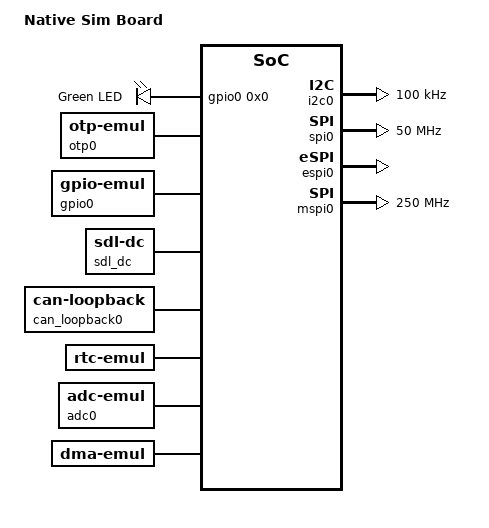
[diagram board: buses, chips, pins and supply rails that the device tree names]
/dts-v1/;

/* node '/' defined in zephyr/dts/common/skeleton.dtsi:9 */
/ {
	#address-cells = < 0x1 >;    /* in zephyr/dts/common/skeleton.dtsi:10 */
	#size-cells = < 0x1 >;       /* in zephyr/dts/common/skeleton.dtsi:11 */
	model = "Native Sim Board";  /* in zephyr/boards/native/native_sim/native_sim.dts:16 */
	compatible = "zephyr,posix"; /* in zephyr/boards/native/native_sim/native_sim.dts:17 */

	/* node '/chosen' defined in zephyr/dts/common/skeleton.dtsi:13 */
	chosen {
		zephyr,console = &uart0;                     /* in zephyr/boards/native/native_sim/native_sim.dts:20 */
		zephyr,shell-uart = &uart0;                  /* in zephyr/boards/native/native_sim/native_sim.dts:21 */
		zephyr,uart-mcumgr = &uart0;                 /* in zephyr/boards/native/native_sim/native_sim.dts:22 */
		zephyr,flash = &flash0;                      /* in zephyr/boards/native/native_sim/native_sim.dts:23 */
		zephyr,entropy = &rng;                       /* in zephyr/boards/native/native_sim/native_sim.dts:24 */
		zephyr,flash-controller = &flashcontroller0; /* in zephyr/boards/native/native_sim/native_sim.dts:25 */
		zephyr,display = &sdl_dc;                    /* in zephyr/boards/native/native_sim/native_sim.dts:26 */
		zephyr,canbus = &can_loopback0;              /* in zephyr/boards/native/native_sim/native_sim.dts:27 */
		zephyr,code-partition = &slot0_partition;    /* in zephyr/boards/native/native_sim/native_sim.dts:28 */
		zephyr,bt-hci = &bt_hci_userchan;            /* in zephyr/boards/native/native_sim/native_sim.dts:29 */
		zephyr,touch = &input_sdl_touch;             /* in zephyr/boards/native/native_sim/native_sim.dts:30 */
	};

	/* node '/aliases' defined in zephyr/dts/common/skeleton.dtsi:15 */
	aliases {
		codec0 = &audio_codec; /* in zephyr/boards/native/native_sim/native_sim.dts:34 */
		dmic0 = &dmic0;        /* in zephyr/boards/native/native_sim/native_sim.dts:35 */
		eeprom-0 = &eeprom0;   /* in zephyr/boards/native/native_sim/native_sim.dts:36 */
		i2c-0 = &i2c0;         /* in zephyr/boards/native/native_sim/native_sim.dts:37 */
		i2s-node0 = &i2s_rxtx; /* in zephyr/boards/native/native_sim/native_sim.dts:38 */
		spi-0 = &spi0;         /* in zephyr/boards/native/native_sim/native_sim.dts:39 */
		led0 = &led0;          /* in zephyr/boards/native/native_sim/native_sim.dts:40 */
		rtc = &rtc;            /* in zephyr/boards/native/native_sim/native_sim.dts:41 */
	};

	/* node '/leds' defined in zephyr/boards/native/native_sim/native_sim.dts:44 */
	leds: leds {
		compatible = "gpio-leds"; /* in zephyr/boards/native/native_sim/native_sim.dts:45 */

		/* node '/leds/led_0' defined in zephyr/boards/native/native_sim/native_sim.dts:47 */
		led0: led_0 {
			gpios = < &gpio0 0x0 0x0 >; /* in zephyr/boards/native/native_sim/native_sim.dts:48 */
			label = "Green LED";        /* in zephyr/boards/native/native_sim/native_sim.dts:49 */
		};
	};

	/* node '/cpus' defined in zephyr/boards/native/native_sim/native_sim.dts:53 */
	cpus {
		timebase-frequency = < 0xf4240 >; /* in zephyr/boards/native/native_sim/native_sim.dts:54 */
		#address-cells = < 0x1 >;         /* in zephyr/boards/native/native_sim/native_sim.dts:55 */
		#size-cells = < 0x0 >;            /* in zephyr/boards/native/native_sim/native_sim.dts:56 */

		/* node '/cpus/cpu@0' defined in zephyr/boards/native/native_sim/native_sim.dts:58 */
		cpu0: cpu@0 {
			compatible = "zephyr,native-sim-cpu"; /* in zephyr/boards/native/native_sim/native_sim.dts:59 */
			reg = < 0x0 >;                        /* in zephyr/boards/native/native_sim/native_sim.dts:60 */
		};
	};

	/* node '/flash-controller@0' defined in zephyr/boards/native/native_sim/native_sim.dts:64 */
	flashcontroller0: flash-controller@0 {
		compatible = "zephyr,sim-flash"; /* in zephyr/boards/native/native_sim/native_sim.dts:65 */
		reg = < 0x0 0x200000 >;          /* in zephyr/boards/native/native_sim/native_sim.dts:66 */
		ranges;                          /* in zephyr/boards/native/native_sim/native_sim.dts:67 */
		#address-cells = < 0x1 >;        /* in zephyr/boards/native/native_sim/native_sim.dts:69 */
		#size-cells = < 0x1 >;           /* in zephyr/boards/native/native_sim/native_sim.dts:70 */
		erase-value = < 0xff >;          /* in zephyr/boards/native/native_sim/native_sim.dts:71 */

		/* node '/flash-controller@0/flash@0' defined in zephyr/boards/native/native_sim/native_sim.dts:73 */
		flash0: flash@0 {
			status = "okay";               /* in zephyr/boards/native/native_sim/native_sim.dts:74 */
			compatible = "soc-nv-flash";   /* in zephyr/boards/native/native_sim/native_sim.dts:75 */
			erase-block-size = < 0x1000 >; /* in zephyr/boards/native/native_sim/native_sim.dts:76 */
			write-block-size = < 0x1 >;    /* in zephyr/boards/native/native_sim/native_sim.dts:77 */
			reg = < 0x0 0x200000 >;        /* in zephyr/boards/native/native_sim/native_sim.dts:78 */
			ranges = < 0x0 0x0 0x200000 >; /* in zephyr/boards/native/native_sim/native_sim.dts:79 */
			#address-cells = < 0x1 >;      /* in zephyr/boards/native/native_sim/native_sim.dts:80 */
			#size-cells = < 0x1 >;         /* in zephyr/boards/native/native_sim/native_sim.dts:81 */

			/* node '/flash-controller@0/flash@0/partitions' defined in zephyr/boards/native/native_sim/native_sim.dts:83 */
			partitions {
				ranges;                   /* in zephyr/boards/native/native_sim/native_sim.dts:84 */
				#address-cells = < 0x1 >; /* in zephyr/boards/native/native_sim/native_sim.dts:85 */
				#size-cells = < 0x1 >;    /* in zephyr/boards/native/native_sim/native_sim.dts:86 */

				/* node '/flash-controller@0/flash@0/partitions/partition@0' defined in zephyr/boards/native/native_sim/native_sim.dts:88 */
				boot_partition: partition@0 {
					compatible = "zephyr,mapped-partition"; /* in zephyr/boards/native/native_sim/native_sim.dts:89 */
					label = "mcuboot";                      /* in zephyr/boards/native/native_sim/native_sim.dts:90 */
					reg = < 0x0 0xc000 >;                   /* in zephyr/boards/native/native_sim/native_sim.dts:91 */
				};

				/* node '/flash-controller@0/flash@0/partitions/partition@c000' defined in zephyr/boards/native/native_sim/native_sim.dts:94 */
				slot0_partition: partition@c000 {
					compatible = "zephyr,mapped-partition"; /* in zephyr/boards/native/native_sim/native_sim.dts:95 */
					label = "image-0";                      /* in zephyr/boards/native/native_sim/native_sim.dts:96 */
					reg = < 0xc000 0x69000 >;               /* in zephyr/boards/native/native_sim/native_sim.dts:97 */
				};

				/* node '/flash-controller@0/flash@0/partitions/partition@75000' defined in zephyr/boards/native/native_sim/native_sim.dts:100 */
				slot1_partition: partition@75000 {
					compatible = "zephyr,mapped-partition"; /* in zephyr/boards/native/native_sim/native_sim.dts:101 */
					label = "image-1";                      /* in zephyr/boards/native/native_sim/native_sim.dts:102 */
					reg = < 0x75000 0x69000 >;              /* in zephyr/boards/native/native_sim/native_sim.dts:103 */
				};

				/* node '/flash-controller@0/flash@0/partitions/partition@de000' defined in zephyr/boards/native/native_sim/native_sim.dts:106 */
				scratch_partition: partition@de000 {
					compatible = "zephyr,mapped-partition"; /* in zephyr/boards/native/native_sim/native_sim.dts:107 */
					label = "image-scratch";                /* in zephyr/boards/native/native_sim/native_sim.dts:108 */
					reg = < 0xde000 0x1e000 >;              /* in zephyr/boards/native/native_sim/native_sim.dts:109 */
				};

				/* node '/flash-controller@0/flash@0/partitions/partition@fc000' defined in zephyr/boards/native/native_sim/native_sim.dts:112 */
				storage_partition: partition@fc000 {
					compatible = "zephyr,mapped-partition"; /* in zephyr/boards/native/native_sim/native_sim.dts:113 */
					label = "storage";                      /* in zephyr/boards/native/native_sim/native_sim.dts:114 */
					reg = < 0xfc000 0x4000 >;               /* in zephyr/boards/native/native_sim/native_sim.dts:115 */
				};
			};
		};
	};

	/* node '/eeprom' defined in zephyr/boards/native/native_sim/native_sim.dts:121 */
	eeprom0: eeprom {
		status = "okay";                  /* in zephyr/boards/native/native_sim/native_sim.dts:122 */
		compatible = "zephyr,sim-eeprom"; /* in zephyr/boards/native/native_sim/native_sim.dts:123 */
		size = < 0x8000 >;                /* in zephyr/boards/native/native_sim/native_sim.dts:124 */
	};

	/* node '/otp' defined in zephyr/boards/native/native_sim/native_sim.dts:127 */
	otp0: otp {
		compatible = "zephyr,otp-emul"; /* in zephyr/boards/native/native_sim/native_sim.dts:128 */
		size = < 0x400 >;               /* in zephyr/boards/native/native_sim/native_sim.dts:129 */
		status = "okay";                /* in zephyr/boards/native/native_sim/native_sim.dts:130 */
	};

	/* node '/i2c@100' defined in zephyr/boards/native/native_sim/native_sim.dts:133 */
	i2c0: i2c@100 {
		status = "okay";                           /* in zephyr/boards/native/native_sim/native_sim.dts:134 */
		compatible = "zephyr,i2c-emul-controller"; /* in zephyr/boards/native/native_sim/native_sim.dts:135 */
		clock-frequency = < 0x186a0 >;             /* in zephyr/boards/native/native_sim/native_sim.dts:136 */
		#address-cells = < 0x1 >;                  /* in zephyr/boards/native/native_sim/native_sim.dts:137 */
		#size-cells = < 0x0 >;                     /* in zephyr/boards/native/native_sim/native_sim.dts:138 */
		#forward-cells = < 0x1 >;                  /* in zephyr/boards/native/native_sim/native_sim.dts:139 */
		reg = < 0x100 0x4 >;                       /* in zephyr/boards/native/native_sim/native_sim.dts:140 */
	};

	/* node '/spi@200' defined in zephyr/boards/native/native_sim/native_sim.dts:143 */
	spi0: spi@200 {
		status = "okay";                           /* in zephyr/boards/native/native_sim/native_sim.dts:144 */
		compatible = "zephyr,spi-emul-controller"; /* in zephyr/boards/native/native_sim/native_sim.dts:145 */
		clock-frequency = < 0x2faf080 >;           /* in zephyr/boards/native/native_sim/native_sim.dts:146 */
		#address-cells = < 0x1 >;                  /* in zephyr/boards/native/native_sim/native_sim.dts:147 */
		#size-cells = < 0x0 >;                     /* in zephyr/boards/native/native_sim/native_sim.dts:148 */
		reg = < 0x200 0x4 >;                       /* in zephyr/boards/native/native_sim/native_sim.dts:149 */
	};

	/* node '/espi@300' defined in zephyr/boards/native/native_sim/native_sim.dts:152 */
	espi0: espi@300 {
		status = "okay";                            /* in zephyr/boards/native/native_sim/native_sim.dts:153 */
		compatible = "zephyr,espi-emul-controller"; /* in zephyr/boards/native/native_sim/native_sim.dts:154 */
		reg = < 0x300 0x4 >;                        /* in zephyr/boards/native/native_sim/native_sim.dts:155 */
		#address-cells = < 0x1 >;                   /* in zephyr/boards/native/native_sim/native_sim.dts:156 */
		#size-cells = < 0x0 >;                      /* in zephyr/boards/native/native_sim/native_sim.dts:157 */
	};

	/* node '/mspi@400' defined in zephyr/boards/native/native_sim/native_sim.dts:160 */
	mspi0: mspi@400 {
		status = "okay";                            /* in zephyr/boards/native/native_sim/native_sim.dts:161 */
		compatible = "zephyr,mspi-emul-controller"; /* in zephyr/boards/native/native_sim/native_sim.dts:162 */
		clock-frequency = < 0xee6b280 >;            /* in zephyr/boards/native/native_sim/native_sim.dts:163 */
		reg = < 0x400 0x4 >;                        /* in zephyr/boards/native/native_sim/native_sim.dts:164 */
		#address-cells = < 0x1 >;                   /* in zephyr/boards/native/native_sim/native_sim.dts:165 */
		#size-cells = < 0x0 >;                      /* in zephyr/boards/native/native_sim/native_sim.dts:166 */
	};

	/* node '/uart' defined in zephyr/boards/native/native_sim/native_sim.dts:169 */
	uart0: uart {
		status = "okay";                       /* in zephyr/boards/native/native_sim/native_sim.dts:170 */
		compatible = "zephyr,native-pty-uart"; /* in zephyr/boards/native/native_sim/native_sim.dts:171 */
		current-speed = < 0x0 >;               /* in zephyr/boards/native/native_sim/native_sim.dts:175 */
	};

	/* node '/uart_1' defined in zephyr/boards/native/native_sim/native_sim.dts:178 */
	uart1: uart_1 {
		status = "disabled";                   /* in zephyr/boards/native/native_sim/native_sim.dts:179 */
		compatible = "zephyr,native-pty-uart"; /* in zephyr/boards/native/native_sim/native_sim.dts:180 */
		current-speed = < 0x0 >;               /* in zephyr/boards/native/native_sim/native_sim.dts:184 */
	};

	/* node '/rng' defined in zephyr/boards/native/native_sim/native_sim.dts:187 */
	rng: rng {
		status = "okay";                      /* in zephyr/boards/native/native_sim/native_sim.dts:188 */
		compatible = "zephyr,native-sim-rng"; /* in zephyr/boards/native/native_sim/native_sim.dts:189 */
	};

	/* node '/counter' defined in zephyr/boards/native/native_sim/native_sim.dts:192 */
	counter0: counter {
		status = "okay";                          /* in zephyr/boards/native/native_sim/native_sim.dts:193 */
		compatible = "zephyr,native-sim-counter"; /* in zephyr/boards/native/native_sim/native_sim.dts:194 */
		#counter-capture-cells = < 0x2 >;         /* in zephyr/boards/native/native_sim/native_sim.dts:195 */
	};

	/* node '/gpio_emul' defined in zephyr/boards/native/native_sim/native_sim.dts:198 */
	gpio0: gpio_emul {
		status = "okay";                 /* in zephyr/boards/native/native_sim/native_sim.dts:199 */
		compatible = "zephyr,gpio-emul"; /* in zephyr/boards/native/native_sim/native_sim.dts:200 */
		rising-edge;                     /* in zephyr/boards/native/native_sim/native_sim.dts:201 */
		falling-edge;                    /* in zephyr/boards/native/native_sim/native_sim.dts:202 */
		high-level;                      /* in zephyr/boards/native/native_sim/native_sim.dts:203 */
		low-level;                       /* in zephyr/boards/native/native_sim/native_sim.dts:204 */
		gpio-controller;                 /* in zephyr/boards/native/native_sim/native_sim.dts:205 */
		#gpio-cells = < 0x2 >;           /* in zephyr/boards/native/native_sim/native_sim.dts:206 */
		phandle = < 0x1 >;               /* in zephyr/boards/native/native_sim/native_sim.dts:48 */
	};

	/* node '/udc0' defined in zephyr/boards/native/native_sim/native_sim.dts:209 */
	zephyr_udc0: udc0 {
		compatible = "zephyr,native-posix-udc"; /* in zephyr/boards/native/native_sim/native_sim.dts:210 */
	};

	/* node '/sdl_dc' defined in zephyr/boards/native/native_sim/native_sim.dts:213 */
	sdl_dc: sdl_dc {
		compatible = "zephyr,sdl-dc"; /* in zephyr/boards/native/native_sim/native_sim.dts:214 */
		pixel-format = < 0x8 >;       /* in zephyr/boards/native/native_sim/native_sim.dts:215 */
		height = < 0xf0 >;            /* in zephyr/boards/native/native_sim/native_sim.dts:216 */
		width = < 0x140 >;            /* in zephyr/boards/native/native_sim/native_sim.dts:217 */
		phandle = < 0x2 >;            /* in zephyr/boards/native/native_sim/native_sim.dts:222 */
	};

	/* node '/input-sdl-touch' defined in zephyr/boards/native/native_sim/native_sim.dts:220 */
	input_sdl_touch: input-sdl-touch {
		compatible = "zephyr,input-sdl-touch"; /* in zephyr/boards/native/native_sim/native_sim.dts:221 */
		display = < &sdl_dc >;                 /* in zephyr/boards/native/native_sim/native_sim.dts:222 */
	};

	/* node '/can_loopback0' defined in zephyr/boards/native/native_sim/native_sim.dts:225 */
	can_loopback0: can_loopback0 {
		status = "okay";                    /* in zephyr/boards/native/native_sim/native_sim.dts:226 */
		compatible = "zephyr,can-loopback"; /* in zephyr/boards/native/native_sim/native_sim.dts:227 */
	};

	/* node '/can' defined in zephyr/boards/native/native_sim/native_sim.dts:230 */
	can0: can {
		status = "disabled";                    /* in zephyr/boards/native/native_sim/native_sim.dts:231 */
		compatible = "zephyr,native-linux-can"; /* in zephyr/boards/native/native_sim/native_sim.dts:232 */
		host-interface = "zcan0";               /* in zephyr/boards/native/native_sim/native_sim.dts:236 */
	};

	/* node '/rtc' defined in zephyr/boards/native/native_sim/native_sim.dts:239 */
	rtc: rtc {
		status = "okay";                /* in zephyr/boards/native/native_sim/native_sim.dts:240 */
		compatible = "zephyr,rtc-emul"; /* in zephyr/boards/native/native_sim/native_sim.dts:241 */
		alarms-count = < 0x2 >;         /* in zephyr/boards/native/native_sim/native_sim.dts:242 */
	};

	/* node '/adc' defined in zephyr/boards/native/native_sim/native_sim.dts:245 */
	adc0: adc {
		compatible = "zephyr,adc-emul"; /* in zephyr/boards/native/native_sim/native_sim.dts:246 */
		nchannels = < 0x2 >;            /* in zephyr/boards/native/native_sim/native_sim.dts:247 */
		#io-channel-cells = < 0x1 >;    /* in zephyr/boards/native/native_sim/native_sim.dts:248 */
		status = "okay";                /* in zephyr/boards/native/native_sim/native_sim.dts:249 */
	};

	/* node '/audio_codec' defined in zephyr/boards/native/native_sim/native_sim.dts:252 */
	audio_codec: audio_codec {
		compatible = "zephyr,dummy-codec"; /* in zephyr/boards/native/native_sim/native_sim.dts:253 */
		status = "okay";                   /* in zephyr/boards/native/native_sim/native_sim.dts:254 */
	};

	/* node '/dmic0' defined in zephyr/boards/native/native_sim/native_sim.dts:257 */
	dmic0: dmic0 {
		compatible = "zephyr,native-sim-dmic"; /* in zephyr/boards/native/native_sim/native_sim.dts:258 */
		status = "okay";                       /* in zephyr/boards/native/native_sim/native_sim.dts:259 */
	};

	/* node '/i2s_rx' defined in zephyr/boards/native/native_sim/native_sim.dts:262 */
	i2s_rx0: i2s_rx {
		compatible = "zephyr,native-sim-i2s"; /* in zephyr/boards/native/native_sim/native_sim.dts:263 */
		status = "okay";                      /* in zephyr/boards/native/native_sim/native_sim.dts:264 */
		stream-direction = "rx";              /* in zephyr/boards/native/native_sim/native_sim.dts:265 */
	};

	/* node '/i2s_rxtx' defined in zephyr/boards/native/native_sim/native_sim.dts:268 */
	i2s_rxtx: i2s_rxtx {
		compatible = "zephyr,native-sim-i2s"; /* in zephyr/boards/native/native_sim/native_sim.dts:269 */
		status = "okay";                      /* in zephyr/boards/native/native_sim/native_sim.dts:270 */
		stream-direction = "both";            /* in zephyr/boards/native/native_sim/native_sim.dts:271 */
	};

	/* node '/i2s_tx' defined in zephyr/boards/native/native_sim/native_sim.dts:274 */
	i2s_tx0: i2s_tx {
		compatible = "zephyr,native-sim-i2s"; /* in zephyr/boards/native/native_sim/native_sim.dts:275 */
		status = "okay";                      /* in zephyr/boards/native/native_sim/native_sim.dts:276 */
		stream-direction = "tx";              /* in zephyr/boards/native/native_sim/native_sim.dts:277 */
	};

	/* node '/dma' defined in zephyr/boards/native/native_sim/native_sim.dts:280 */
	dma: dma {
		compatible = "zephyr,dma-emul"; /* in zephyr/boards/native/native_sim/native_sim.dts:281 */
		#dma-cells = < 0x1 >;           /* in zephyr/boards/native/native_sim/native_sim.dts:282 */
		stack-size = < 0x1000 >;        /* in zephyr/boards/native/native_sim/native_sim.dts:283 */
	};

	/* node '/bt_hci_userchan' defined in zephyr/boards/native/native_sim/native_sim.dts:286 */
	bt_hci_userchan: bt_hci_userchan {
		compatible = "zephyr,bt-hci-userchan"; /* in zephyr/boards/native/native_sim/native_sim.dts:287 */
		status = "okay";                       /* in zephyr/boards/native/native_sim/native_sim.dts:288 */
	};

	/* node '/performance-states' defined in zephyr/boards/native/native_sim/native_sim.dts:291 */
	performance-states {

		/* node '/performance-states/pstate_0' defined in zephyr/boards/native/native_sim/native_sim.dts:292 */
		pstate_0: pstate_0 {
			compatible = "zephyr,native-sim-pstate"; /* in zephyr/boards/native/native_sim/native_sim.dts:293 */
			load-threshold = < 0x32 >;               /* in zephyr/boards/native/native_sim/native_sim.dts:294 */
			pstate-id = < 0x0 >;                     /* in zephyr/boards/native/native_sim/native_sim.dts:295 */
		};

		/* node '/performance-states/pstate_1' defined in zephyr/boards/native/native_sim/native_sim.dts:298 */
		pstate_1: pstate_1 {
			compatible = "zephyr,native-sim-pstate"; /* in zephyr/boards/native/native_sim/native_sim.dts:299 */
			load-threshold = < 0x14 >;               /* in zephyr/boards/native/native_sim/native_sim.dts:300 */
			pstate-id = < 0x1 >;                     /* in zephyr/boards/native/native_sim/native_sim.dts:301 */
		};

		/* node '/performance-states/pstate_2' defined in zephyr/boards/native/native_sim/native_sim.dts:304 */
		pstate_2: pstate_2 {
			compatible = "zephyr,native-sim-pstate"; /* in zephyr/boards/native/native_sim/native_sim.dts:305 */
			load-threshold = < 0x0 >;                /* in zephyr/boards/native/native_sim/native_sim.dts:306 */
			pstate-id = < 0x2 >;                     /* in zephyr/boards/native/native_sim/native_sim.dts:307 */
		};
	};

	/* node '/zeth0' defined in zephyr/boards/native/native_sim/native_sim.dts:311 */
	zeth0: zeth0 {
		compatible = "zephyr,native-tap";               /* in zephyr/boards/native/native_sim/native_sim.dts:312 */
		status = "okay";                                /* in zephyr/boards/native/native_sim/native_sim.dts:313 */
		zephyr,random-mac-address;                      /* in zephyr/boards/native/native_sim/native_sim.dts:314 */
		zephyr,mac-address-prefix = [ 00 00 5E 00 53 ]; /* in zephyr/boards/native/native_sim/native_sim.dts:315 */
		host-interface = "zeth";                        /* in zephyr/boards/native/native_sim/native_sim.dts:316 */

		/* node '/zeth0/ptp_clock' defined in zephyr/boards/native/native_sim/native_sim.dts:318 */
		ptp_clock: ptp_clock {
			compatible = "zephyr,native-ptp-clock"; /* in zephyr/boards/native/native_sim/native_sim.dts:319 */
			status = "okay";                        /* in zephyr/boards/native/native_sim/native_sim.dts:320 */
		};
	};
};
